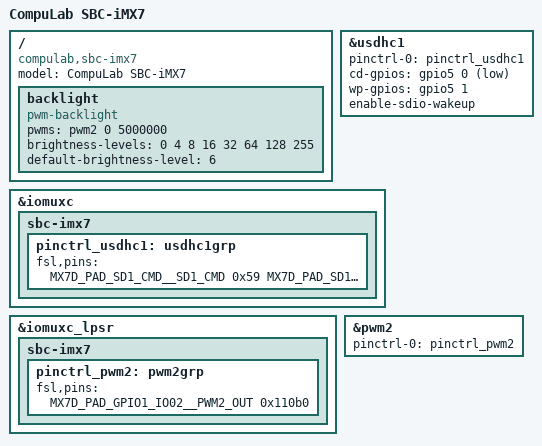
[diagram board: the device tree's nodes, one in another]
/*
 * Support for CompuLab SBC-iMX7 Single Board Computer
 *
 * Copyright (C) 2015 CompuLab Ltd. - http://www.compulab.co.il/
 * Author: Ilya Ledvich <ilya@compulab.co.il>
 *
 * This program is free software; you can redistribute it and/or modify
 * it under the terms of the GNU General Public License version 2 as
 * published by the Free Software Foundation.
 */

#include "imx7d-cl-som-imx7.dts"

/ {
	model = "CompuLab SBC-iMX7";
	compatible = "compulab,sbc-imx7", "compulab,cl-som-imx7", "fsl,imx7d";

	backlight {
		compatible = "pwm-backlight";
		pwms = <&pwm2 0 5000000>;
		brightness-levels = <0 4 8 16 32 64 128 255>;
		default-brightness-level = <6>;
		status = "okay";
	};
};

&usdhc1 {
	pinctrl-names = "default";
	pinctrl-0 = <&pinctrl_usdhc1>;
	cd-gpios = <&gpio5 0 GPIO_ACTIVE_LOW>;
	wp-gpios = <&gpio5 1 GPIO_ACTIVE_HIGH>;
	enable-sdio-wakeup;
	status = "okay";
};

&iomuxc {
	sbc-imx7 {
		pinctrl_usdhc1: usdhc1grp {
			fsl,pins = <
				MX7D_PAD_SD1_CMD__SD1_CMD		0x59
				MX7D_PAD_SD1_CLK__SD1_CLK		0x19
				MX7D_PAD_SD1_DATA0__SD1_DATA0		0x59
				MX7D_PAD_SD1_DATA1__SD1_DATA1		0x59
				MX7D_PAD_SD1_DATA2__SD1_DATA2		0x59
				MX7D_PAD_SD1_DATA3__SD1_DATA3		0x59
				MX7D_PAD_SD1_CD_B__GPIO5_IO0		0x59 /* CD */
				MX7D_PAD_SD1_WP__GPIO5_IO1		0x59 /* WP */
			>;
		};
	};
};

&iomuxc_lpsr {
	sbc-imx7 {
		pinctrl_pwm2: pwm2grp {
			fsl,pins = <
				MX7D_PAD_GPIO1_IO02__PWM2_OUT		0x110b0
			>;
		};
	};
};

&pwm2 {
	pinctrl-names = "default";
	pinctrl-0 = <&pinctrl_pwm2>;
	status = "okay";
};
